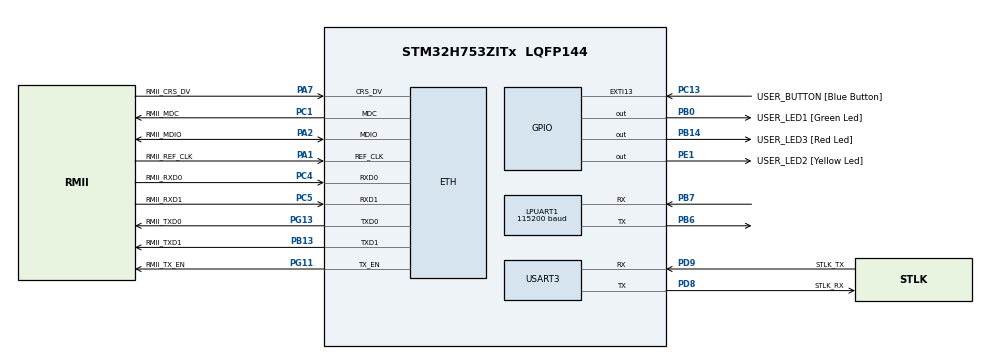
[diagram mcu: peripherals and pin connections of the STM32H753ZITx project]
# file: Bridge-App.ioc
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CORTEX_M7.AccessPermission-Cortex_Memory_Protection_Unit_Region0_Settings=MPU_REGION_FULL_ACCESS
CORTEX_M7.AccessPermission-Cortex_Memory_Protection_Unit_Region1_Settings=MPU_REGION_FULL_ACCESS
CORTEX_M7.AccessPermission_S-Cortex_Memory_Protection_Unit_Region1_Settings_S=MPU_REGION_FULL_ACCESS
CORTEX_M7.AccessPermission_S-Cortex_Memory_Protection_Unit_Region2_Settings_S=MPU_REGION_FULL_ACCESS
CORTEX_M7.AccessPermission_Spec=MPU_REGION_NO_ACCESS
CORTEX_M7.BaseAddress-Cortex_Memory_Protection_Unit_Region0_Settings=0x30040000
CORTEX_M7.BaseAddress-Cortex_Memory_Protection_Unit_Region1_Settings=0x30044000
CORTEX_M7.BaseAddress_S-Cortex_Memory_Protection_Unit_Region1_Settings_S=0x30020000
CORTEX_M7.BaseAddress_S-Cortex_Memory_Protection_Unit_Region2_Settings_S=0x30040000
CORTEX_M7.BaseAddress_Spec=0x0
CORTEX_M7.CPU_DCache=Disabled
CORTEX_M7.CPU_ICache=Disabled
CORTEX_M7.DisableExec_S-Cortex_Memory_Protection_Unit_Region1_Settings_S=MPU_INSTRUCTION_ACCESS_DISABLE
CORTEX_M7.DisableExec_S-Cortex_Memory_Protection_Unit_Region2_Settings_S=MPU_INSTRUCTION_ACCESS_DISABLE
CORTEX_M7.DisableExec_Spec=MPU_INSTRUCTION_ACCESS_DISABLE
CORTEX_M7.Enable-Cortex_Memory_Protection_Unit_Region0_Settings=MPU_REGION_ENABLE
CORTEX_M7.Enable-Cortex_Memory_Protection_Unit_Region1_Settings=MPU_REGION_ENABLE
CORTEX_M7.Enable_S-Cortex_Memory_Protection_Unit_Region1_Settings_S=MPU_REGION_ENABLE
CORTEX_M7.Enable_S-Cortex_Memory_Protection_Unit_Region2_Settings_S=MPU_REGION_ENABLE
CORTEX_M7.IsBufferable-Cortex_Memory_Protection_Unit_Region0_Settings=MPU_ACCESS_BUFFERABLE
CORTEX_M7.IsBufferable_S-Cortex_Memory_Protection_Unit_Region2_Settings_S=MPU_ACCESS_BUFFERABLE
CORTEX_M7.IsBufferable_Spec=MPU_ACCESS_NOT_BUFFERABLE
CORTEX_M7.IsShareable-Cortex_Memory_Protection_Unit_Region0_Settings=MPU_ACCESS_NOT_SHAREABLE
CORTEX_M7.IsShareable-Cortex_Memory_Protection_Unit_Region1_Settings=MPU_ACCESS_SHAREABLE
CORTEX_M7.IsShareable_S-Cortex_Memory_Protection_Unit_Region1_Settings_S=MPU_ACCESS_NOT_SHAREABLE
CORTEX_M7.IsShareable_S-Cortex_Memory_Protection_Unit_Region2_Settings_S=MPU_ACCESS_SHAREABLE
CORTEX_M7.IsShareable_Spec=MPU_ACCESS_SHAREABLE
CORTEX_M7.MPU_Control=MPU_PRIVILEGED_DEFAULT
CORTEX_M7.Size-Cortex_Memory_Protection_Unit_Region0_Settings=MPU_REGION_SIZE_512B
CORTEX_M7.Size-Cortex_Memory_Protection_Unit_Region1_Settings=MPU_REGION_SIZE_16KB
CORTEX_M7.Size_S-Cortex_Memory_Protection_Unit_Region1_Settings_S=MPU_REGION_SIZE_128KB
CORTEX_M7.Size_S-Cortex_Memory_Protection_Unit_Region2_Settings_S=MPU_REGION_SIZE_512B
CORTEX_M7.Size_Spec=MPU_REGION_SIZE_4GB
CORTEX_M7.SubRegionDisable-Cortex_Memory_Protection_Unit_Region0_Settings=0x0
CORTEX_M7.SubRegionDisable_Spec=0x87
CORTEX_M7.TypeExtField-Cortex_Memory_Protection_Unit_Region1_Settings=MPU_TEX_LEVEL1
CORTEX_M7.TypeExtField_S-Cortex_Memory_Protection_Unit_Region1_Settings_S=MPU_TEX_LEVEL1
CORTEX_M7.default_mode_Activation=1
CRYP.Algorithm=CRYP_AES_CCM
ETH.ETH_RX_DESC_CNT=4
ETH.ETH_TX_DESC_CNT=4
ETH.MediaInterface=HAL_ETH_RMII_MODE
ETH.RxBufferAddress=0x30020000
ETH.RxDescAddress=0x30040000
ETH.TxDescAddress=0x30040100
LPUART1.BaudRate=115200
Mcu.Family=STM32H7
Mcu.Name=STM32H753ZITx
Mcu.Package=LQFP144
NVIC.ETH_IRQn=true\:0\:0\:false\:false\:true\:true\:true\:true
NVIC.EXTI15_10_IRQn=true\:5\:0\:true\:false\:true\:true\:true\:true
NVIC.LPUART1_IRQn=true\:5\:0\:true\:false\:true\:true\:true\:true
NVIC.PriorityGroup=NVIC_PRIORITYGROUP_4
NVIC.TIM6_DAC_IRQn=true\:15\:0\:true\:false\:true\:false\:true\:true
NVIC.TimeBase=TIM6_DAC_IRQn
NVIC.TimeBaseIP=TIM6
NVIC.USART3_IRQn=true\:5\:0\:true\:false\:true\:true\:true\:true
PA1.GPIO_Label=RMII_REF_CLK
PA1.GPIO_Speed=GPIO_SPEED_FREQ_VERY_HIGH
PA1.Mode=RMII
PA1.Signal=ETH_REF_CLK
PA2.GPIO_Label=RMII_MDIO
PA2.GPIO_Speed=GPIO_SPEED_FREQ_VERY_HIGH
PA2.Mode=RMII
PA2.Signal=ETH_MDIO
PA7.GPIO_Label=RMII_CRS_DV
PA7.GPIO_Speed=GPIO_SPEED_FREQ_VERY_HIGH
PA7.Mode=RMII
PA7.Signal=ETH_CRS_DV
PB0.GPIO_Label=USER_LED1 [Green Led]
PB0.GPIO_PuPd=GPIO_PULLDOWN
PB0.Signal=GPIO_Output
PB13.GPIO_Label=RMII_TXD1
PB13.GPIO_Speed=GPIO_SPEED_FREQ_VERY_HIGH
PB13.Mode=RMII
PB13.Signal=ETH_TXD1
PB14.GPIO_Label=USER_LED3 [Red Led]
PB14.GPIO_PuPd=GPIO_PULLDOWN
PB14.Signal=GPIO_Output
PB6.GPIO_Speed=GPIO_SPEED_FREQ_MEDIUM
PB6.Mode=Asynchronous
PB6.Signal=LPUART1_TX
PB7.GPIO_PuPd=GPIO_NOPULL
PB7.GPIO_Speed=GPIO_SPEED_FREQ_MEDIUM
PB7.Mode=Asynchronous
PB7.Signal=LPUART1_RX
PC1.GPIO_Label=RMII_MDC
PC1.GPIO_Speed=GPIO_SPEED_FREQ_VERY_HIGH
PC1.Mode=RMII
PC1.Signal=ETH_MDC
PC13.GPIO_Label=USER_BUTTON [Blue Button]
PC13.GPIO_ModeDefaultEXTI=GPIO_MODE_IT_RISING_FALLING
PC13.Signal=GPXTI13
PC4.GPIO_Label=RMII_RXD0
PC4.GPIO_Speed=GPIO_SPEED_FREQ_VERY_HIGH
PC4.Mode=RMII
PC4.Signal=ETH_RXD0
PC5.GPIO_Label=RMII_RXD1
PC5.GPIO_Speed=GPIO_SPEED_FREQ_VERY_HIGH
PC5.Mode=RMII
PC5.Signal=ETH_RXD1
PD8.GPIO_Label=STLK_RX
PD8.GPIO_PuPd=GPIO_NOPULL
PD8.GPIO_Speed=GPIO_SPEED_FREQ_MEDIUM
PD8.Mode=Asynchronous
PD8.Signal=USART3_TX
PD9.GPIO_Label=STLK_TX
PD9.GPIO_Speed=GPIO_SPEED_FREQ_MEDIUM
PD9.Mode=Asynchronous
PD9.Signal=USART3_RX
PE1.GPIO_Label=USER_LED2 [Yellow Led]
PE1.GPIO_PuPd=GPIO_PULLDOWN
PE1.Signal=GPIO_Output
PG11.GPIO_Label=RMII_TX_EN
PG11.GPIO_Speed=GPIO_SPEED_FREQ_VERY_HIGH
PG11.Mode=RMII
PG11.Signal=ETH_TX_EN
PG13.GPIO_Label=RMII_TXD0
PG13.GPIO_Speed=GPIO_SPEED_FREQ_VERY_HIGH
PG13.Mode=RMII
PG13.Signal=ETH_TXD0
ProjectManager.HeapSize=0x2000
ProjectManager.StackSize=0x1000
ProjectManager.TargetToolchain=STM32CubeIDE
RCC.ADCFreq_Value=129000000
RCC.APB1Freq_Value=120000000
RCC.APB2Freq_Value=120000000
RCC.APB3Freq_Value=120000000
RCC.APB4Freq_Value=120000000
RCC.CortexFreq_Value=480000000
RCC.D1PPRE=RCC_APB3_DIV2
RCC.D2PPRE1=RCC_APB1_DIV2
RCC.D2PPRE2=RCC_APB2_DIV2
RCC.D3PPRE=RCC_APB4_DIV2
RCC.DIVM1=4
RCC.DIVN1=60
RCC.DIVQ1=10
RCC.HCLKFreq_Value=240000000
RCC.HPRE=RCC_HCLK_DIV2
RCC.HSE_VALUE=8000000
RCC.PLLFRACN=0
RCC.PWR_Regulator_Voltage_Scale=PWR_REGULATOR_VOLTAGE_SCALE0
RCC.SYSCLKFreq_VALUE=480000000
RCC.SYSCLKSource=RCC_SYSCLKSOURCE_PLLCLK
RCC.USART234578CLockSelection=RCC_USART234578CLKSOURCE_HSI
RCC.USBFreq_Value=96000000
USART3.VirtualMode-Asynchronous=VM_ASYNC
VP_CRYP_VS_CRYP.Mode=CRYP_Activate
VP_HASH_VS_HASH.Mode=HASH_Activate
VP_RNG_VS_RNG.Mode=RNG_Activate
VP_RTC_VS_RTC_Activate.Mode=RTC_Enabled
VP_RTC_VS_RTC_Calendar.Mode=RTC_Calendar
VP_SYS_VS_tim6.Mode=TIM6
board=NUCLEO-H753ZI

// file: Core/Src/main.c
/* USER CODE BEGIN Header */
/**
  ******************************************************************************
  * @file           : main.c
  * @brief          : Main program body
  ******************************************************************************
  * @attention
  *
  * Copyright (c) 2025 STMicroelectronics.
  * All rights reserved.
  *
  * This software is licensed under terms that can be found in the LICENSE file
  * in the root directory of this software component.
  * If no LICENSE file comes with this software, it is provided AS-IS.
  *
  ******************************************************************************
  */
/* USER CODE END Header */
#include "main.h"
#include "string.h"

/* USER CODE BEGIN Includes */
#include "FreeRTOS.h"
#include "task.h"

#include "AppEntry.h"
/* USER CODE END Includes */

#if 0
#if defined ( __ICCARM__ ) /*!< IAR Compiler */
#pragma location=0x30040000
ETH_DMADescTypeDef  DMARxDscrTab[ETH_RX_DESC_CNT]; /* Ethernet Rx DMA Descriptors */
#pragma location=0x30040100
ETH_DMADescTypeDef  DMATxDscrTab[ETH_TX_DESC_CNT]; /* Ethernet Tx DMA Descriptors */

#elif defined ( __CC_ARM )  /* MDK ARM Compiler */

__attribute__((at(0x30040000))) ETH_DMADescTypeDef  DMARxDscrTab[ETH_RX_DESC_CNT]; /* Ethernet Rx DMA Descriptors */
__attribute__((at(0x30040100))) ETH_DMADescTypeDef  DMATxDscrTab[ETH_TX_DESC_CNT]; /* Ethernet Tx DMA Descriptors */

#elif defined ( __GNUC__ ) /* GNU Compiler */

ETH_DMADescTypeDef DMARxDscrTab[ETH_RX_DESC_CNT] __attribute__((section(".RxDecripSection"))); /* Ethernet Rx DMA Descriptors */
ETH_DMADescTypeDef DMATxDscrTab[ETH_TX_DESC_CNT] __attribute__((section(".TxDecripSection")));   /* Ethernet Tx DMA Descriptors */
#endif

ETH_TxPacketConfig TxConfig;
#endif /* 0 */

CRYP_HandleTypeDef hcryp;
__ALIGN_BEGIN static const uint32_t pKeyCRYP[4] __ALIGN_END = {
                            0x00000000,0x00000000,0x00000000,0x00000000};
__ALIGN_BEGIN static const uint32_t HeaderCRYP[4] __ALIGN_END = {
                            0x00000000000000000000000000000000};
__ALIGN_BEGIN static const uint32_t B0CRYP[4] __ALIGN_END = {
                            0x00000000,0x00000000,0x00000000,0x00000000};

HASH_HandleTypeDef hhash;

UART_HandleTypeDef hlpuart1;
UART_HandleTypeDef huart3;

RNG_HandleTypeDef hrng;

RTC_HandleTypeDef hrtc;

void SystemClock_Config(void);
static void MPU_Config(void);
static void MX_GPIO_Init(void);
static void MX_CRYP_Init(void);
static void MX_HASH_Init(void);
static void MX_RNG_Init(void);
static void MX_RTC_Init(void);
static void MX_LPUART1_UART_Init(void);
static void MX_USART3_UART_Init(void);

int main(void)
{

  /* USER CODE BEGIN 1 */
  bool result;
  /* USER CODE END 1 */

  /* MPU Configuration--------------------------------------------------------*/
  MPU_Config();

  /* MCU Configuration--------------------------------------------------------*/

  /* Reset of all peripherals, Initializes the Flash interface and the Systick. */
  HAL_Init();

  /* Configure the system clock */
  SystemClock_Config();

  /* Initialize all configured peripherals */
  MX_GPIO_Init();
  MX_CRYP_Init();
  MX_HASH_Init();
  MX_RNG_Init();
  MX_RTC_Init();
  MX_LPUART1_UART_Init();
  MX_USART3_UART_Init();
  /* USER CODE BEGIN 2 */
  result = AppEntryInit();
  if (result == true)
  {
    result = AppEntryStart();
  }
  if (result == true)
  {
    vTaskStartScheduler();
  }
  /* USER CODE END 2 */

  /* Infinite loop */
  while (1)
  {

  }
}

void SystemClock_Config(void)
{
  RCC_OscInitTypeDef RCC_OscInitStruct = {0};
  RCC_ClkInitTypeDef RCC_ClkInitStruct = {0};

  /** Supply configuration update enable
  */
  HAL_PWREx_ConfigSupply(PWR_LDO_SUPPLY);

  /** Configure the main internal regulator output voltage
  */
  __HAL_PWR_VOLTAGESCALING_CONFIG(PWR_REGULATOR_VOLTAGE_SCALE0);

  while(!__HAL_PWR_GET_FLAG(PWR_FLAG_VOSRDY)) {}

  /** Initializes the RCC Oscillators according to the specified parameters
  * in the RCC_OscInitTypeDef structure.
  */
  RCC_OscInitStruct.OscillatorType = RCC_OSCILLATORTYPE_HSI48|RCC_OSCILLATORTYPE_HSI
                              |RCC_OSCILLATORTYPE_LSI;
  RCC_OscInitStruct.HSIState = RCC_HSI_DIV1;
  RCC_OscInitStruct.HSICalibrationValue = RCC_HSICALIBRATION_DEFAULT;
  RCC_OscInitStruct.LSIState = RCC_LSI_ON;
  RCC_OscInitStruct.HSI48State = RCC_HSI48_ON;
  RCC_OscInitStruct.PLL.PLLState = RCC_PLL_ON;
  RCC_OscInitStruct.PLL.PLLSource = RCC_PLLSOURCE_HSI;
  RCC_OscInitStruct.PLL.PLLM = 4;
  RCC_OscInitStruct.PLL.PLLN = 60;
  RCC_OscInitStruct.PLL.PLLP = 2;
  RCC_OscInitStruct.PLL.PLLQ = 10;
  RCC_OscInitStruct.PLL.PLLR = 2;
  RCC_OscInitStruct.PLL.PLLRGE = RCC_PLL1VCIRANGE_3;
  RCC_OscInitStruct.PLL.PLLVCOSEL = RCC_PLL1VCOWIDE;
  RCC_OscInitStruct.PLL.PLLFRACN = 0;
  if (HAL_RCC_OscConfig(&RCC_OscInitStruct) != HAL_OK)
  {
    Error_Handler();
  }

  /** Initializes the CPU, AHB and APB buses clocks
  */
  RCC_ClkInitStruct.ClockType = RCC_CLOCKTYPE_HCLK|RCC_CLOCKTYPE_SYSCLK
                              |RCC_CLOCKTYPE_PCLK1|RCC_CLOCKTYPE_PCLK2
                              |RCC_CLOCKTYPE_D3PCLK1|RCC_CLOCKTYPE_D1PCLK1;
  RCC_ClkInitStruct.SYSCLKSource = RCC_SYSCLKSOURCE_PLLCLK;
  RCC_ClkInitStruct.SYSCLKDivider = RCC_SYSCLK_DIV1;
  RCC_ClkInitStruct.AHBCLKDivider = RCC_HCLK_DIV2;
  RCC_ClkInitStruct.APB3CLKDivider = RCC_APB3_DIV2;
  RCC_ClkInitStruct.APB1CLKDivider = RCC_APB1_DIV2;
  RCC_ClkInitStruct.APB2CLKDivider = RCC_APB2_DIV2;
  RCC_ClkInitStruct.APB4CLKDivider = RCC_APB4_DIV2;

  if (HAL_RCC_ClockConfig(&RCC_ClkInitStruct, FLASH_LATENCY_4) != HAL_OK)
  {
    Error_Handler();
  }
}

static void MX_CRYP_Init(void)
{

  hcryp.Instance = CRYP;
  hcryp.Init.DataType = CRYP_DATATYPE_32B;
  hcryp.Init.KeySize = CRYP_KEYSIZE_128B;
  hcryp.Init.pKey = (uint32_t *)pKeyCRYP;
  hcryp.Init.Algorithm = CRYP_AES_CCM;
  hcryp.Init.Header = (uint32_t *)HeaderCRYP;
  hcryp.Init.HeaderSize = 4;
  hcryp.Init.B0 = (uint32_t *)B0CRYP;
  if (HAL_CRYP_Init(&hcryp) != HAL_OK)
  {
    Error_Handler();
  }

}

static void MX_HASH_Init(void)
{

  hhash.Init.DataType = HASH_DATATYPE_32B;
  if (HAL_HASH_Init(&hhash) != HAL_OK)
  {
    Error_Handler();
  }

}

static void MX_LPUART1_UART_Init(void)
{

  hlpuart1.Instance = LPUART1;
  hlpuart1.Init.BaudRate = 115200;
  hlpuart1.Init.WordLength = UART_WORDLENGTH_8B;
  hlpuart1.Init.StopBits = UART_STOPBITS_1;
  hlpuart1.Init.Parity = UART_PARITY_NONE;
  hlpuart1.Init.Mode = UART_MODE_TX_RX;
  hlpuart1.Init.HwFlowCtl = UART_HWCONTROL_NONE;
  hlpuart1.Init.OneBitSampling = UART_ONE_BIT_SAMPLE_DISABLE;
  hlpuart1.Init.ClockPrescaler = UART_PRESCALER_DIV1;
  hlpuart1.AdvancedInit.AdvFeatureInit = UART_ADVFEATURE_NO_INIT;
  hlpuart1.FifoMode = UART_FIFOMODE_DISABLE;
  if (HAL_UART_Init(&hlpuart1) != HAL_OK)
  {
    Error_Handler();
  }
  if (HAL_UARTEx_SetTxFifoThreshold(&hlpuart1, UART_TXFIFO_THRESHOLD_1_8) != HAL_OK)
  {
    Error_Handler();
  }
  if (HAL_UARTEx_SetRxFifoThreshold(&hlpuart1, UART_RXFIFO_THRESHOLD_1_8) != HAL_OK)
  {
    Error_Handler();
  }
  if (HAL_UARTEx_DisableFifoMode(&hlpuart1) != HAL_OK)
  {
    Error_Handler();
  }

}

static void MX_USART3_UART_Init(void)
{

  huart3.Instance = USART3;
  huart3.Init.BaudRate = 115200;
  huart3.Init.WordLength = UART_WORDLENGTH_8B;
  huart3.Init.StopBits = UART_STOPBITS_1;
  huart3.Init.Parity = UART_PARITY_NONE;
  huart3.Init.Mode = UART_MODE_TX_RX;
  huart3.Init.HwFlowCtl = UART_HWCONTROL_NONE;
  huart3.Init.OverSampling = UART_OVERSAMPLING_16;
  huart3.Init.OneBitSampling = UART_ONE_BIT_SAMPLE_DISABLE;
  huart3.Init.ClockPrescaler = UART_PRESCALER_DIV1;
  huart3.AdvancedInit.AdvFeatureInit = UART_ADVFEATURE_NO_INIT;
  if (HAL_UART_Init(&huart3) != HAL_OK)
  {
    Error_Handler();
  }
  if (HAL_UARTEx_SetTxFifoThreshold(&huart3, UART_TXFIFO_THRESHOLD_1_8) != HAL_OK)
  {
    Error_Handler();
  }
  if (HAL_UARTEx_SetRxFifoThreshold(&huart3, UART_RXFIFO_THRESHOLD_1_8) != HAL_OK)
  {
    Error_Handler();
  }
  if (HAL_UARTEx_DisableFifoMode(&huart3) != HAL_OK)
  {
    Error_Handler();
  }

}

static void MX_RNG_Init(void)
{

  hrng.Instance = RNG;
  hrng.Init.ClockErrorDetection = RNG_CED_ENABLE;
  if (HAL_RNG_Init(&hrng) != HAL_OK)
  {
    Error_Handler();
  }

}

static void MX_RTC_Init(void)
{

  RTC_TimeTypeDef sTime = {0};
  RTC_DateTypeDef sDate = {0};

  /** Initialize RTC Only
  */
  hrtc.Instance = RTC;
  hrtc.Init.HourFormat = RTC_HOURFORMAT_24;
  hrtc.Init.AsynchPrediv = 127;
  hrtc.Init.SynchPrediv = 255;
  hrtc.Init.OutPut = RTC_OUTPUT_DISABLE;
  hrtc.Init.OutPutPolarity = RTC_OUTPUT_POLARITY_HIGH;
  hrtc.Init.OutPutType = RTC_OUTPUT_TYPE_OPENDRAIN;
  hrtc.Init.OutPutRemap = RTC_OUTPUT_REMAP_NONE;
  if (HAL_RTC_Init(&hrtc) != HAL_OK)
  {
    Error_Handler();
  }

  /** Initialize RTC and set the Time and Date
  */
  sTime.Hours = 0x0;
  sTime.Minutes = 0x0;
  sTime.Seconds = 0x0;
  sTime.DayLightSaving = RTC_DAYLIGHTSAVING_NONE;
  sTime.StoreOperation = RTC_STOREOPERATION_RESET;
  if (HAL_RTC_SetTime(&hrtc, &sTime, RTC_FORMAT_BCD) != HAL_OK)
  {
    Error_Handler();
  }
  sDate.WeekDay = RTC_WEEKDAY_MONDAY;
  sDate.Month = RTC_MONTH_JANUARY;
  sDate.Date = 0x1;
  sDate.Year = 0x0;

  if (HAL_RTC_SetDate(&hrtc, &sDate, RTC_FORMAT_BCD) != HAL_OK)
  {
    Error_Handler();
  }

}

static void MX_GPIO_Init(void)
{
  GPIO_InitTypeDef GPIO_InitStruct = {0};

  /* GPIO Ports Clock Enable */
  __HAL_RCC_GPIOE_CLK_ENABLE();
  __HAL_RCC_GPIOC_CLK_ENABLE();
  __HAL_RCC_GPIOF_CLK_ENABLE();
  __HAL_RCC_GPIOH_CLK_ENABLE();
  __HAL_RCC_GPIOA_CLK_ENABLE();
  __HAL_RCC_GPIOB_CLK_ENABLE();
  __HAL_RCC_GPIOG_CLK_ENABLE();
  __HAL_RCC_GPIOD_CLK_ENABLE();

  /*Configure GPIO pin Output Level */
  HAL_GPIO_WritePin(GPIOB, USER_LED1_Pin|USER_LED3_Pin, GPIO_PIN_RESET);

  /*Configure GPIO pin Output Level */
  HAL_GPIO_WritePin(USER_LED2_GPIO_Port, USER_LED2_Pin, GPIO_PIN_RESET);

  /*Configure GPIO pins : PE2 PE3 PE4 PE5
                           PE6 PE7 PE8 PE9
                           PE10 PE11 PE12 PE13
                           PE14 PE15 PE0 */
  GPIO_InitStruct.Pin = GPIO_PIN_2|GPIO_PIN_3|GPIO_PIN_4|GPIO_PIN_5
                          |GPIO_PIN_6|GPIO_PIN_7|GPIO_PIN_8|GPIO_PIN_9
                          |GPIO_PIN_10|GPIO_PIN_11|GPIO_PIN_12|GPIO_PIN_13
                          |GPIO_PIN_14|GPIO_PIN_15|GPIO_PIN_0;
  GPIO_InitStruct.Mode = GPIO_MODE_ANALOG;
  GPIO_InitStruct.Pull = GPIO_NOPULL;
  HAL_GPIO_Init(GPIOE, &GPIO_InitStruct);

  /*Configure GPIO pin : USER_BUTTON_Pin */
  GPIO_InitStruct.Pin = USER_BUTTON_Pin;
  GPIO_InitStruct.Mode = GPIO_MODE_IT_RISING_FALLING;
  GPIO_InitStruct.Pull = GPIO_NOPULL;
  HAL_GPIO_Init(USER_BUTTON_GPIO_Port, &GPIO_InitStruct);

  /*Configure GPIO pins : PC14 PC15 PC0 PC2
                           PC3 PC6 PC7 PC8
                           PC9 PC10 PC11 PC12 */
  GPIO_InitStruct.Pin = GPIO_PIN_14|GPIO_PIN_15|GPIO_PIN_0|GPIO_PIN_2
                          |GPIO_PIN_3|GPIO_PIN_6|GPIO_PIN_7|GPIO_PIN_8
                          |GPIO_PIN_9|GPIO_PIN_10|GPIO_PIN_11|GPIO_PIN_12;
  GPIO_InitStruct.Mode = GPIO_MODE_ANALOG;
  GPIO_InitStruct.Pull = GPIO_NOPULL;
  HAL_GPIO_Init(GPIOC, &GPIO_InitStruct);

  /*Configure GPIO pins : PF0 PF1 PF2 PF3
                           PF4 PF5 PF6 PF7
                           PF8 PF9 PF10 PF11
                           PF12 PF13 PF14 PF15 */
  GPIO_InitStruct.Pin = GPIO_PIN_0|GPIO_PIN_1|GPIO_PIN_2|GPIO_PIN_3
                          |GPIO_PIN_4|GPIO_PIN_5|GPIO_PIN_6|GPIO_PIN_7
                          |GPIO_PIN_8|GPIO_PIN_9|GPIO_PIN_10|GPIO_PIN_11
                          |GPIO_PIN_12|GPIO_PIN_13|GPIO_PIN_14|GPIO_PIN_15;
  GPIO_InitStruct.Mode = GPIO_MODE_ANALOG;
  GPIO_InitStruct.Pull = GPIO_NOPULL;
  HAL_GPIO_Init(GPIOF, &GPIO_InitStruct);

  /*Configure GPIO pins : PH0 PH1 */
  GPIO_InitStruct.Pin = GPIO_PIN_0|GPIO_PIN_1;
  GPIO_InitStruct.Mode = GPIO_MODE_ANALOG;
  GPIO_InitStruct.Pull = GPIO_NOPULL;
  HAL_GPIO_Init(GPIOH, &GPIO_InitStruct);

  /*Configure GPIO pins : PA0 PA3 PA4 PA5
                           PA6 PA8 PA9 PA10
                           PA11 PA12 PA13 PA14
                           PA15 */
  GPIO_InitStruct.Pin = GPIO_PIN_0|GPIO_PIN_3|GPIO_PIN_4|GPIO_PIN_5
                          |GPIO_PIN_6|GPIO_PIN_8|GPIO_PIN_9|GPIO_PIN_10
                          |GPIO_PIN_11|GPIO_PIN_12|GPIO_PIN_13|GPIO_PIN_14
                          |GPIO_PIN_15;
  GPIO_InitStruct.Mode = GPIO_MODE_ANALOG;
  GPIO_InitStruct.Pull = GPIO_NOPULL;
  HAL_GPIO_Init(GPIOA, &GPIO_InitStruct);

  /*Configure GPIO pins : USER_LED1_Pin USER_LED3_Pin */
  GPIO_InitStruct.Pin = USER_LED1_Pin|USER_LED3_Pin;
  GPIO_InitStruct.Mode = GPIO_MODE_OUTPUT_PP;
  GPIO_InitStruct.Pull = GPIO_PULLDOWN;
  GPIO_InitStruct.Speed = GPIO_SPEED_FREQ_LOW;
  HAL_GPIO_Init(GPIOB, &GPIO_InitStruct);

  /*Configure GPIO pins : PB1 PB2 PB10 PB11
                           PB12 PB15 PB3 PB4
                           PB5 PB8 PB9 */
  GPIO_InitStruct.Pin = GPIO_PIN_1|GPIO_PIN_2|GPIO_PIN_10|GPIO_PIN_11
                          |GPIO_PIN_12|GPIO_PIN_15|GPIO_PIN_3|GPIO_PIN_4
                          |GPIO_PIN_5|GPIO_PIN_8|GPIO_PIN_9;
  GPIO_InitStruct.Mode = GPIO_MODE_ANALOG;
  GPIO_InitStruct.Pull = GPIO_NOPULL;
  HAL_GPIO_Init(GPIOB, &GPIO_InitStruct);

  /*Configure GPIO pins : PG0 PG1 PG2 PG3
                           PG4 PG5 PG6 PG7
                           PG8 PG9 PG10 PG12
                           PG14 PG15 */
  GPIO_InitStruct.Pin = GPIO_PIN_0|GPIO_PIN_1|GPIO_PIN_2|GPIO_PIN_3
                          |GPIO_PIN_4|GPIO_PIN_5|GPIO_PIN_6|GPIO_PIN_7
                          |GPIO_PIN_8|GPIO_PIN_9|GPIO_PIN_10|GPIO_PIN_12
                          |GPIO_PIN_14|GPIO_PIN_15;
  GPIO_InitStruct.Mode = GPIO_MODE_ANALOG;
  GPIO_InitStruct.Pull = GPIO_NOPULL;
  HAL_GPIO_Init(GPIOG, &GPIO_InitStruct);

  /*Configure GPIO pins : PD10 PD11 PD12 PD13
                           PD14 PD15 PD0 PD1
                           PD2 PD3 PD4 PD5
                           PD6 PD7 */
  GPIO_InitStruct.Pin = GPIO_PIN_10|GPIO_PIN_11|GPIO_PIN_12|GPIO_PIN_13
                          |GPIO_PIN_14|GPIO_PIN_15|GPIO_PIN_0|GPIO_PIN_1
                          |GPIO_PIN_2|GPIO_PIN_3|GPIO_PIN_4|GPIO_PIN_5
                          |GPIO_PIN_6|GPIO_PIN_7;
  GPIO_InitStruct.Mode = GPIO_MODE_ANALOG;
  GPIO_InitStruct.Pull = GPIO_NOPULL;
  HAL_GPIO_Init(GPIOD, &GPIO_InitStruct);

  /*Configure GPIO pin : USER_LED2_Pin */
  GPIO_InitStruct.Pin = USER_LED2_Pin;
  GPIO_InitStruct.Mode = GPIO_MODE_OUTPUT_PP;
  GPIO_InitStruct.Pull = GPIO_PULLDOWN;
  GPIO_InitStruct.Speed = GPIO_SPEED_FREQ_LOW;
  HAL_GPIO_Init(USER_LED2_GPIO_Port, &GPIO_InitStruct);

  /* EXTI interrupt init*/
  HAL_NVIC_SetPriority(USER_BUTTON_EXTI_IRQn, 5, 0);
  HAL_NVIC_EnableIRQ(USER_BUTTON_EXTI_IRQn);

}

 /* MPU Configuration */

void MPU_Config(void)
{
  MPU_Region_InitTypeDef MPU_InitStruct = {0};

  /* Disables the MPU */
  HAL_MPU_Disable();

  /** Initializes and configures the Region and the memory to be protected
  */
  MPU_InitStruct.Enable = MPU_REGION_ENABLE;
  MPU_InitStruct.Number = MPU_REGION_NUMBER0;
  MPU_InitStruct.BaseAddress = 0x0;
  MPU_InitStruct.Size = MPU_REGION_SIZE_4GB;
  MPU_InitStruct.SubRegionDisable = 0x87;
  MPU_InitStruct.TypeExtField = MPU_TEX_LEVEL0;
  MPU_InitStruct.AccessPermission = MPU_REGION_NO_ACCESS;
  MPU_InitStruct.DisableExec = MPU_INSTRUCTION_ACCESS_DISABLE;
  MPU_InitStruct.IsShareable = MPU_ACCESS_SHAREABLE;
  MPU_InitStruct.IsCacheable = MPU_ACCESS_NOT_CACHEABLE;
  MPU_InitStruct.IsBufferable = MPU_ACCESS_NOT_BUFFERABLE;

  HAL_MPU_ConfigRegion(&MPU_InitStruct);

  /** Initializes and configures the Region and the memory to be protected
  */
  MPU_InitStruct.Number = MPU_REGION_NUMBER1;
  MPU_InitStruct.BaseAddress = 0x30020000;
  MPU_InitStruct.Size = MPU_REGION_SIZE_128KB;
  MPU_InitStruct.SubRegionDisable = 0x0;
  MPU_InitStruct.TypeExtField = MPU_TEX_LEVEL1;
  MPU_InitStruct.AccessPermission = MPU_REGION_FULL_ACCESS;
  MPU_InitStruct.IsShareable = MPU_ACCESS_NOT_SHAREABLE;

  HAL_MPU_ConfigRegion(&MPU_InitStruct);

  /** Initializes and configures the Region and the memory to be protected
  */
  MPU_InitStruct.Number = MPU_REGION_NUMBER2;
  MPU_InitStruct.BaseAddress = 0x30040000;
  MPU_InitStruct.Size = MPU_REGION_SIZE_512B;
  MPU_InitStruct.TypeExtField = MPU_TEX_LEVEL0;
  MPU_InitStruct.IsShareable = MPU_ACCESS_SHAREABLE;
  MPU_InitStruct.IsBufferable = MPU_ACCESS_BUFFERABLE;

  HAL_MPU_ConfigRegion(&MPU_InitStruct);
  /* Enables the MPU */
  HAL_MPU_Enable(MPU_PRIVILEGED_DEFAULT);

}

void HAL_TIM_PeriodElapsedCallback(TIM_HandleTypeDef *htim)
{
  if (htim->Instance == TIM6)
  {
    HAL_IncTick();
  }
}

void Error_Handler(void)
{
  /* USER CODE BEGIN Error_Handler_Debug */
  /* User can add his own implementation to report the HAL error return state */
  __disable_irq();
  while (1)
  {
    HAL_Delay(100);
  }
  /* USER CODE END Error_Handler_Debug */
}
